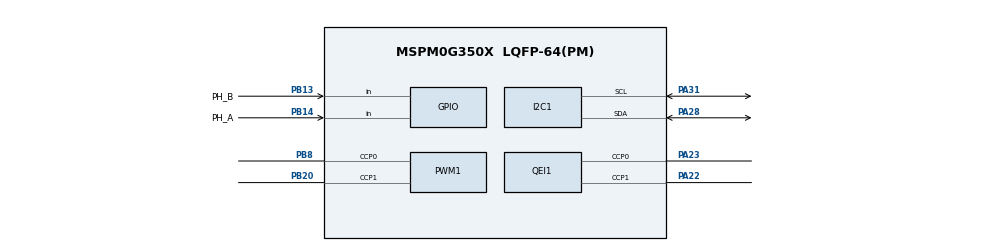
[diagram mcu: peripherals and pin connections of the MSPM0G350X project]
/**
 * @cliArgs --device "MSPM0G350X" --part "Default" --package "LQFP-64(PM)" --product "mspm0_sdk@2.05.01.00"
 * @versions {"tool":"1.24.0+4110"}
 */

/**
 * Import the modules used in this configuration.
 */
const GPIO    = scripting.addModule("/ti/driverlib/GPIO", {}, false);
const GPIO1   = GPIO.addInstance();
const GPIO2   = GPIO.addInstance();
const GPIO3   = GPIO.addInstance();
const GPIO4   = GPIO.addInstance();
const I2C     = scripting.addModule("/ti/driverlib/I2C", {}, false);
const I2C1    = I2C.addInstance();
const PWM     = scripting.addModule("/ti/driverlib/PWM", {}, false);
const PWM1    = PWM.addInstance();
const QEI     = scripting.addModule("/ti/driverlib/QEI", {}, false);
const QEI1    = QEI.addInstance();
const SYSCTL  = scripting.addModule("/ti/driverlib/SYSCTL");
const SYSTICK = scripting.addModule("/ti/driverlib/SYSTICK");
const TIMER   = scripting.addModule("/ti/driverlib/TIMER", {}, false);
const TIMER1  = TIMER.addInstance();

/**
 * Write custom configuration values to the imported modules.
 */
GPIO1.$name                              = "SENSOR_PORT";
GPIO1.associatedPins.create(8);
GPIO1.associatedPins[0].$name            = "S1";
GPIO1.associatedPins[0].direction        = "INPUT";
GPIO1.associatedPins[0].internalResistor = "PULL_UP";
GPIO1.associatedPins[0].assignedPort     = "PORTA";
GPIO1.associatedPins[0].assignedPin      = "2";
GPIO1.associatedPins[1].$name            = "S2";
GPIO1.associatedPins[1].direction        = "INPUT";
GPIO1.associatedPins[1].internalResistor = "PULL_UP";
GPIO1.associatedPins[1].assignedPort     = "PORTA";
GPIO1.associatedPins[1].assignedPin      = "3";
GPIO1.associatedPins[2].$name            = "S3";
GPIO1.associatedPins[2].direction        = "INPUT";
GPIO1.associatedPins[2].internalResistor = "PULL_UP";
GPIO1.associatedPins[2].assignedPort     = "PORTA";
GPIO1.associatedPins[2].assignedPin      = "4";
GPIO1.associatedPins[3].$name            = "S4";
GPIO1.associatedPins[3].direction        = "INPUT";
GPIO1.associatedPins[3].internalResistor = "PULL_UP";
GPIO1.associatedPins[3].assignedPort     = "PORTA";
GPIO1.associatedPins[3].assignedPin      = "5";
GPIO1.associatedPins[4].$name            = "S5";
GPIO1.associatedPins[4].direction        = "INPUT";
GPIO1.associatedPins[4].internalResistor = "PULL_UP";
GPIO1.associatedPins[4].assignedPort     = "PORTA";
GPIO1.associatedPins[4].assignedPin      = "6";
GPIO1.associatedPins[5].$name            = "S6";
GPIO1.associatedPins[5].direction        = "INPUT";
GPIO1.associatedPins[5].internalResistor = "PULL_UP";
GPIO1.associatedPins[5].assignedPort     = "PORTB";
GPIO1.associatedPins[5].assignedPin      = "0";
GPIO1.associatedPins[6].$name            = "S7";
GPIO1.associatedPins[6].direction        = "INPUT";
GPIO1.associatedPins[6].internalResistor = "PULL_UP";
GPIO1.associatedPins[6].assignedPort     = "PORTB";
GPIO1.associatedPins[6].assignedPin      = "1";
GPIO1.associatedPins[7].$name            = "S8";
GPIO1.associatedPins[7].direction        = "INPUT";
GPIO1.associatedPins[7].internalResistor = "PULL_UP";
GPIO1.associatedPins[7].assignedPort     = "PORTA";
GPIO1.associatedPins[7].assignedPin      = "7";

const Board = scripting.addModule("/ti/driverlib/Board", {}, false);

GPIO2.$name                          = "MOTOR_DIR";
GPIO2.associatedPins.create(4);
GPIO2.associatedPins[0].assignedPort = "PORTB";
GPIO2.associatedPins[0].assignedPin  = "2";
GPIO2.associatedPins[0].$name        = "AIN1";
GPIO2.associatedPins[1].assignedPort = "PORTB";
GPIO2.associatedPins[1].assignedPin  = "3";
GPIO2.associatedPins[1].$name        = "AIN2";
GPIO2.associatedPins[2].assignedPort = "PORTB";
GPIO2.associatedPins[2].assignedPin  = "4";
GPIO2.associatedPins[2].$name        = "BIN1";
GPIO2.associatedPins[3].assignedPort = "PORTB";
GPIO2.associatedPins[3].assignedPin  = "5";
GPIO2.associatedPins[3].$name        = "BIN2";

GPIO3.$name                              = "KEY_PORT";
GPIO3.associatedPins.create(4);
GPIO3.associatedPins[0].$name            = "K0";
GPIO3.associatedPins[0].direction        = "INPUT";
GPIO3.associatedPins[0].internalResistor = "PULL_UP";
GPIO3.associatedPins[0].assignedPort     = "PORTA";
GPIO3.associatedPins[0].assignedPin      = "15";
GPIO3.associatedPins[1].$name            = "K1";
GPIO3.associatedPins[1].direction        = "INPUT";
GPIO3.associatedPins[1].internalResistor = "PULL_UP";
GPIO3.associatedPins[1].assignedPort     = "PORTA";
GPIO3.associatedPins[1].assignedPin      = "16";
GPIO3.associatedPins[2].$name            = "K2";
GPIO3.associatedPins[2].assignedPort     = "PORTA";
GPIO3.associatedPins[2].assignedPin      = "17";
GPIO3.associatedPins[2].direction        = "INPUT";
GPIO3.associatedPins[2].internalResistor = "PULL_UP";
GPIO3.associatedPins[3].$name            = "K3";
GPIO3.associatedPins[3].assignedPort     = "PORTA";
GPIO3.associatedPins[3].assignedPin      = "18";
GPIO3.associatedPins[3].direction        = "INPUT";
GPIO3.associatedPins[3].internalResistor = "PULL_UP";

GPIO4.$name                              = "ENCODER_R";
GPIO4.associatedPins.create(2);
GPIO4.associatedPins[0].$name            = "PH_A";
GPIO4.associatedPins[0].direction        = "INPUT";
GPIO4.associatedPins[0].internalResistor = "PULL_UP";
GPIO4.associatedPins[0].polarity         = "RISE";
GPIO4.associatedPins[0].interruptEn      = true;
GPIO4.associatedPins[0].pin.$assign      = "PB14";
GPIO4.associatedPins[1].$name            = "PH_B";
GPIO4.associatedPins[1].internalResistor = "PULL_UP";
GPIO4.associatedPins[1].direction        = "INPUT";
GPIO4.associatedPins[1].pin.$assign      = "PB13";

I2C1.basicEnableController             = true;
I2C1.$name                             = "I2C_OLED";
I2C1.peripheral.sdaPin.$assign         = "PA28";
I2C1.peripheral.sclPin.$assign         = "PA31";
I2C1.sdaPinConfig.hideOutputInversion  = scripting.forceWrite(false);
I2C1.sdaPinConfig.onlyInternalResistor = scripting.forceWrite(false);
I2C1.sdaPinConfig.passedPeripheralType = scripting.forceWrite("Digital");
I2C1.sdaPinConfig.$name                = "ti_driverlib_gpio_GPIOPinGeneric4";
I2C1.sdaPinConfig.enableConfig         = true;
I2C1.sdaPinConfig.internalResistor     = "PULL_UP";
I2C1.sclPinConfig.hideOutputInversion  = scripting.forceWrite(false);
I2C1.sclPinConfig.onlyInternalResistor = scripting.forceWrite(false);
I2C1.sclPinConfig.passedPeripheralType = scripting.forceWrite("Digital");
I2C1.sclPinConfig.$name                = "ti_driverlib_gpio_GPIOPinGeneric5";
I2C1.sclPinConfig.enableConfig         = true;
I2C1.sclPinConfig.internalResistor     = "PULL_UP";

PWM1.$name                              = "PWM_MOTOR";
PWM1.timerCount                         = 7200;
PWM1.peripheral.ccp0Pin.$assign         = "PB8";
PWM1.peripheral.ccp1Pin.$assign         = "PB20";
PWM1.PWM_CHANNEL_0.$name                = "ti_driverlib_pwm_PWMTimerCC0";
PWM1.PWM_CHANNEL_1.$name                = "ti_driverlib_pwm_PWMTimerCC1";
PWM1.ccp0PinConfig.direction            = scripting.forceWrite("OUTPUT");
PWM1.ccp0PinConfig.hideOutputInversion  = scripting.forceWrite(false);
PWM1.ccp0PinConfig.onlyInternalResistor = scripting.forceWrite(false);
PWM1.ccp0PinConfig.passedPeripheralType = scripting.forceWrite("Digital");
PWM1.ccp0PinConfig.$name                = "ti_driverlib_gpio_GPIOPinGeneric0";
PWM1.ccp0PinConfig.enableConfig         = true;
PWM1.ccp1PinConfig.direction            = scripting.forceWrite("OUTPUT");
PWM1.ccp1PinConfig.hideOutputInversion  = scripting.forceWrite(false);
PWM1.ccp1PinConfig.onlyInternalResistor = scripting.forceWrite(false);
PWM1.ccp1PinConfig.passedPeripheralType = scripting.forceWrite("Digital");
PWM1.ccp1PinConfig.$name                = "ti_driverlib_gpio_GPIOPinGeneric1";
PWM1.ccp1PinConfig.enableConfig         = true;

QEI1.$name                              = "ENCODER_L";
QEI1.timerStartTimer                    = true;
QEI1.peripheral.ccp0Pin.$assign         = "PA23";
QEI1.peripheral.ccp1Pin.$assign         = "PA22";
QEI1.ccp0PinConfig.hideOutputInversion  = scripting.forceWrite(false);
QEI1.ccp0PinConfig.onlyInternalResistor = scripting.forceWrite(false);
QEI1.ccp0PinConfig.passedPeripheralType = scripting.forceWrite("Digital");
QEI1.ccp0PinConfig.$name                = "ti_driverlib_gpio_GPIOPinGeneric2";
QEI1.ccp1PinConfig.hideOutputInversion  = scripting.forceWrite(false);
QEI1.ccp1PinConfig.onlyInternalResistor = scripting.forceWrite(false);
QEI1.ccp1PinConfig.passedPeripheralType = scripting.forceWrite("Digital");
QEI1.ccp1PinConfig.$name                = "ti_driverlib_gpio_GPIOPinGeneric3";

SYSCTL.forceDefaultClkConfig = true;

SYSTICK.interruptEnable = true;
SYSTICK.periodEnable    = true;
SYSTICK.period          = 320000;
SYSTICK.systickEnable   = true;

TIMER1.$name = "TIMER_10MS";

/**
 * Pinmux solution for unlocked pins/peripherals. This ensures that minor changes to the automatic solver in a future
 * version of the tool will not impact the pinmux you originally saw.  These lines can be completely deleted in order to
 * re-solve from scratch.
 */
GPIO1.associatedPins[0].pin.$suggestSolution = "PA2";
GPIO1.associatedPins[1].pin.$suggestSolution = "PA3";
GPIO1.associatedPins[2].pin.$suggestSolution = "PA4";
GPIO1.associatedPins[3].pin.$suggestSolution = "PA5";
GPIO1.associatedPins[4].pin.$suggestSolution = "PA6";
GPIO1.associatedPins[5].pin.$suggestSolution = "PB0";
GPIO1.associatedPins[6].pin.$suggestSolution = "PB1";
GPIO1.associatedPins[7].pin.$suggestSolution = "PA7";
Board.peripheral.$suggestSolution            = "DEBUGSS";
Board.peripheral.swclkPin.$suggestSolution   = "PA20";
Board.peripheral.swdioPin.$suggestSolution   = "PA19";
GPIO2.associatedPins[0].pin.$suggestSolution = "PB2";
GPIO2.associatedPins[1].pin.$suggestSolution = "PB3";
GPIO2.associatedPins[2].pin.$suggestSolution = "PB4";
GPIO2.associatedPins[3].pin.$suggestSolution = "PB5";
GPIO3.associatedPins[0].pin.$suggestSolution = "PA15";
GPIO3.associatedPins[1].pin.$suggestSolution = "PA16";
GPIO3.associatedPins[2].pin.$suggestSolution = "PA17";
GPIO3.associatedPins[3].pin.$suggestSolution = "PA18";
I2C1.peripheral.$suggestSolution             = "I2C0";
PWM1.peripheral.$suggestSolution             = "TIMA0";
QEI1.peripheral.$suggestSolution             = "TIMG8";
SYSCTL.peripheral.$suggestSolution           = "SYSCTL";
TIMER1.peripheral.$suggestSolution           = "TIMA1";
